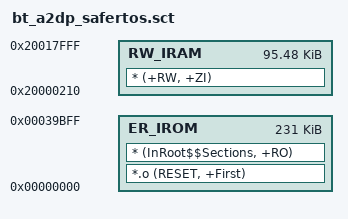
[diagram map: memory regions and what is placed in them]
;******************************************************************************
;
; bt_a2dp_safertos.sct - Linker configuration file for bt_a2dp_safertos.
;
; Copyright (c) 2011-2012 Texas Instruments Incorporated.  All rights reserved.
; Software License Agreement
; 
; Texas Instruments (TI) is supplying this software for use solely and
; exclusively on TI's microcontroller products. The software is owned by
; TI and/or its suppliers, and is protected under applicable copyright
; laws. You may not combine this software with "viral" open-source
; software in order to form a larger program.
; 
; THIS SOFTWARE IS PROVIDED "AS IS" AND WITH ALL FAULTS.
; NO WARRANTIES, WHETHER EXPRESS, IMPLIED OR STATUTORY, INCLUDING, BUT
; NOT LIMITED TO, IMPLIED WARRANTIES OF MERCHANTABILITY AND FITNESS FOR
; A PARTICULAR PURPOSE APPLY TO THIS SOFTWARE. TI SHALL NOT, UNDER ANY
; CIRCUMSTANCES, BE LIABLE FOR SPECIAL, INCIDENTAL, OR CONSEQUENTIAL
; DAMAGES, FOR ANY REASON WHATSOEVER.
; 
; This is part of revision 8555 of the DK-LM3S9B96-EM2-CC2560-BLUETOPIA Firmware Package.
;
;******************************************************************************

LR_IROM 0x00000000 0x00039c00
{
    ;
    ; Specify the Execution Address of the code and the size.
    ;
    ER_IROM 0x00000000 0x00039c00
    {
        *.o (RESET, +First)
        * (InRoot$$Sections, +RO)
    }

    ;
    ; Specify the Execution Address of the data area.
    ;
    RW_IRAM 0x20000210 0x00017df0
    {
        ;
        ; Uncomment the following line in order to use IntRegister().
        ;
        ;* (vtable, +First)
        * (+RW, +ZI)
    }
}
